# STM32L5x2 register map
File version: 1.3
Registers are 32-bit, read-write, reset 0x0 unless marked. A register's access mark holds for its fields unless they carry their own. Offsets are from the block's base; [hi:lo] are bit positions.

## LPUART1 — Universal synchronous asynchronous receiver transmitter
Base 0x40008000
Same registers: SEC_LPUART1 0x50008000
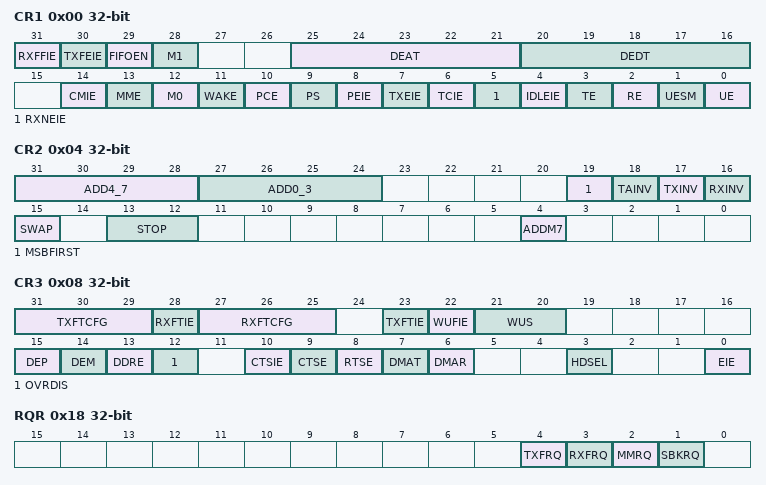
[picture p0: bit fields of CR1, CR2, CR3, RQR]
0x00 CR1 — Control register 1
  [31] RXFFIE
  [30] TXFEIE
  [29] FIFOEN
  [28] M1 — Word length
  [25:21] DEAT
  [20:16] DEDT
  [14] CMIE — Character match interrupt enable
  [13] MME — Mute mode enable
  [12] M0 — Word length
  [11] WAKE — Receiver wakeup method
  [10] PCE — Parity control enable
  [9] PS — Parity selection
  [8] PEIE — PE interrupt enable
  [7] TXEIE — interrupt enable
  [6] TCIE — Transmission complete interrupt enable
  [5] RXNEIE — RXNE interrupt enable
  [4] IDLEIE — IDLE interrupt enable
  [3] TE — Transmitter enable
  [2] RE — Receiver enable
  [1] UESM — USART enable in Stop mode
  [0] UE — USART enable
0x04 CR2 — Control register 2
  [31:28] ADD4_7 — Address of the USART node
  [27:24] ADD0_3 — Address of the USART node
  [19] MSBFIRST — Most significant bit first
  [18] TAINV — Binary data inversion
  [17] TXINV — TX pin active level inversion
  [16] RXINV — RX pin active level inversion
  [15] SWAP — Swap TX/RX pins
  [13:12] STOP — STOP bits
  [4] ADDM7 — 7-bit Address Detection/4-bit Address Detection
0x08 CR3 — Control register 3
  [31:29] TXFTCFG
  [28] RXFTIE
  [27:25] RXFTCFG
  [23] TXFTIE
  [22] WUFIE — Wakeup from Stop mode interrupt enable
  [21:20] WUS — Wakeup from Stop mode interrupt flag selection
  [15] DEP — Driver enable polarity selection
  [14] DEM — Driver enable mode
  [13] DDRE — DMA Disable on Reception Error
  [12] OVRDIS — Overrun Disable
  [10] CTSIE — CTS interrupt enable
  [9] CTSE — CTS enable
  [8] RTSE — RTS enable
  [7] DMAT — DMA enable transmitter
  [6] DMAR — DMA enable receiver
  [3] HDSEL — Half-duplex selection
  [0] EIE — Error interrupt enable
0x0C BRR — Baud rate register
  [19:0] BRR
0x18 RQR wo — Request register
  [4] TXFRQ
  [3] RXFRQ — Receive data flush request
  [2] MMRQ — Mute mode request
  [1] SBKRQ — Send break request
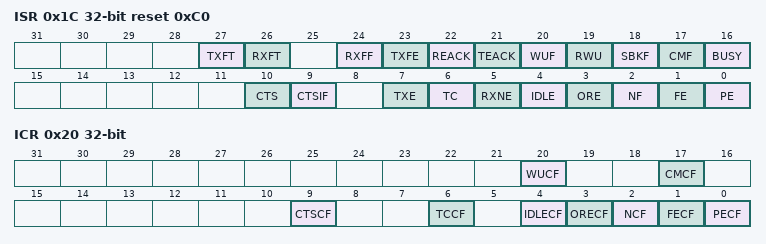
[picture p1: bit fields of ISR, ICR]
0x1C ISR ro reset 0xC0 — Interrupt & status register
  [27] TXFT, [26] RXFT, [24] RXFF, [23] TXFE, [22] REACK, [21] TEACK, [20] WUF, [19] RWU, [18] SBKF, [17] CMF, [16] BUSY, [10] CTS, [9] CTSIF, [7] TXE, [6] TC, [5] RXNE, [4] IDLE, [3] ORE, [2] NF, [1] FE, [0] PE
0x20 ICR wo — Interrupt flag clear register
  [20] WUCF — Wakeup from Stop mode clear flag
  [17] CMCF — Character match clear flag
  [9] CTSCF — CTS clear flag
  [6] TCCF — Transmission complete clear flag
  [4] IDLECF — Idle line detected clear flag
  [3] ORECF — Overrun error clear flag
  [2] NCF — Noise detected clear flag
  [1] FECF — Framing error clear flag
  [0] PECF — Parity error clear flag
0x24 RDR ro — Receive data register
  [8:0] RDR — Receive data value
0x28 TDR — Transmit data register
  [8:0] TDR — Transmit data value
0x2C PRESC
  [3:0] PRESCALER

## COMP — Comparator
Base 0x40010200
Same registers: SEC_COMP 0x50010200
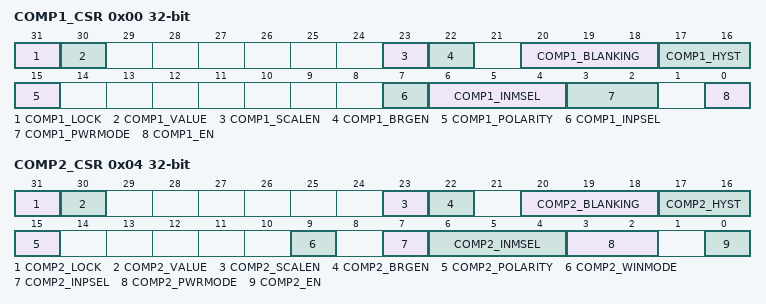
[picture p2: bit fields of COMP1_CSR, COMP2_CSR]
0x00 COMP1_CSR access per field — Comparator 1 control and status register
  [31] COMP1_LOCK wo — COMP1_CSR register lock bit
  [30] COMP1_VALUE ro — Comparator 1 output status bit
  [23] COMP1_SCALEN rw — Voltage scaler enable bit
  [22] COMP1_BRGEN rw — Scaler bridge enable
  [20:18] COMP1_BLANKING rw — Comparator 1 blanking source selection bits
  [17:16] COMP1_HYST rw — Comparator 1 hysteresis selection bits
  [15] COMP1_POLARITY rw — Comparator 1 polarity selection bit
  [7] COMP1_INPSEL rw — Comparator1 input plus selection bit
  [6:4] COMP1_INMSEL rw — Comparator 1 Input Minus connection configuration bit
  [3:2] COMP1_PWRMODE rw — Power Mode of the comparator 1
  [0] COMP1_EN rw — Comparator 1 enable bit
0x04 COMP2_CSR access per field — Comparator 2 control and status register
  [31] COMP2_LOCK wo — COMP2_CSR register lock bit
  [30] COMP2_VALUE ro — Comparator 2 output status bit
  [23] COMP2_SCALEN rw — Voltage scaler enable bit
  [22] COMP2_BRGEN rw — Scaler bridge enable
  [20:18] COMP2_BLANKING rw — Comparator 2 blanking source selection bits
  [17:16] COMP2_HYST rw — Comparator 2 hysteresis selection bits
  [15] COMP2_POLARITY rw — Comparator 2 polarity selection bit
  [9] COMP2_WINMODE rw — Windows mode selection bit
  [7] COMP2_INPSEL rw — Comparator 2 Input Plus connection configuration bit
  [6:4] COMP2_INMSEL rw — Comparator 2 Input Minus connection configuration bit
  [3:2] COMP2_PWRMODE rw — Power Mode of the comparator 2
  [0] COMP2_EN rw — Comparator 2 enable bit
